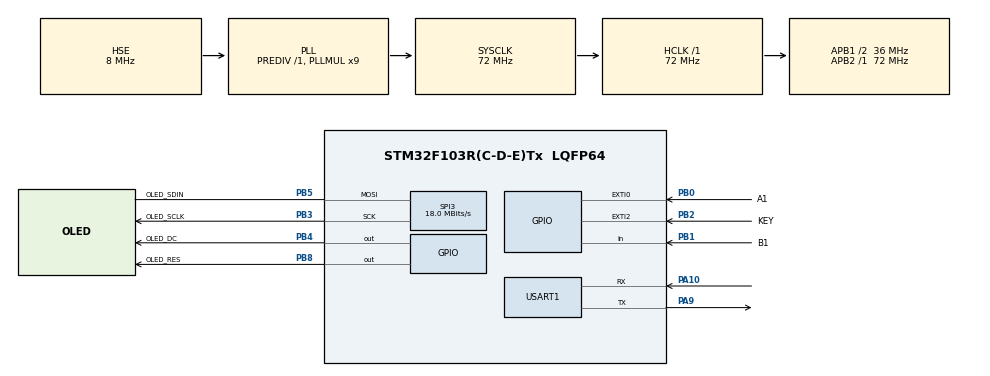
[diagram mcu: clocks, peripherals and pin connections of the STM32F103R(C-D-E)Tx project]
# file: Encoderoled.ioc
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Mcu.Family=STM32F1
Mcu.Name=STM32F103R(C-D-E)Tx
Mcu.Package=LQFP64
NVIC.EXTI0_IRQn=true\:0\:0\:false\:false\:true\:true\:true\:true
NVIC.PriorityGroup=NVIC_PRIORITYGROUP_4
PA10.Mode=Asynchronous
PA10.Signal=USART1_RX
PA13.Mode=Serial_Wire
PA13.Signal=SYS_JTMS-SWDIO
PA14.Mode=Serial_Wire
PA14.Signal=SYS_JTCK-SWCLK
PA9.Mode=Asynchronous
PA9.Signal=USART1_TX
PB0.GPIO_Label=A1
PB0.GPIO_ModeDefaultEXTI=GPIO_MODE_IT_FALLING
PB0.Signal=GPXTI0
PB1.GPIO_Label=B1
PB1.Signal=GPIO_Input
PB2.GPIO_Label=KEY
PB2.GPIO_ModeDefaultEXTI=GPIO_MODE_IT_FALLING
PB2.Signal=GPXTI2
PB3.GPIO_Label=OLED_SCLK
PB3.Mode=Simplex_Bidirectional_Master
PB3.Signal=SPI3_SCK
PB4.GPIO_Label=OLED_DC
PB4.Signal=GPIO_Output
PB5.GPIO_Label=OLED_SDIN
PB5.Mode=Simplex_Bidirectional_Master
PB5.Signal=SPI3_MOSI
PB8.GPIO_Label=OLED_RES
PB8.Signal=GPIO_Output
PD0-OSC_IN.Mode=HSE-External-Oscillator
PD0-OSC_IN.Signal=RCC_OSC_IN
PD1-OSC_OUT.Mode=HSE-External-Oscillator
PD1-OSC_OUT.Signal=RCC_OSC_OUT
ProjectManager.HeapSize=0x200
ProjectManager.StackSize=0x400
ProjectManager.TargetToolchain=MDK-ARM V5.32
RCC.AHBFreq_Value=72000000
RCC.APB1CLKDivider=RCC_HCLK_DIV2
RCC.APB1Freq_Value=36000000
RCC.APB1TimFreq_Value=72000000
RCC.APB2Freq_Value=72000000
RCC.APB2TimFreq_Value=72000000
RCC.HCLKFreq_Value=72000000
RCC.PLLMUL=RCC_PLL_MUL9
RCC.PLLSourceVirtual=RCC_PLLSOURCE_HSE
RCC.SYSCLKFreq_VALUE=72000000
RCC.SYSCLKSource=RCC_SYSCLKSOURCE_PLLCLK
RCC.USBFreq_Value=72000000
SPI3.CalculateBaudRate=18.0 MBits/s
SPI3.Direction=SPI_DIRECTION_1LINE
SPI3.Mode=SPI_MODE_MASTER
SPI3.VirtualType=VM_MASTER
USART1.VirtualMode=VM_ASYNC
board=custom

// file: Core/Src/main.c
/* USER CODE BEGIN Header */
/**
  ******************************************************************************
  * @file           : main.c
  * @brief          : Main program body
  ******************************************************************************
  * @attention
  *
  * Copyright (c) 2026 STMicroelectronics.
  * All rights reserved.
  *
  * This software is licensed under terms that can be found in the LICENSE file
  * in the root directory of this software component.
  * If no LICENSE file comes with this software, it is provided AS-IS.
  *
  ******************************************************************************
  */
/* USER CODE END Header */
#include "main.h"
#include "spi.h"
#include "usart.h"
#include "gpio.h"

/* USER CODE BEGIN Includes */
# include <stdio.h>
#include <stdbool.h>
#include "sh1106oled.h"
#include "sh1106oledfont.h"
#include "Encoder.h"
/* USER CODE END Includes */

void SystemClock_Config(void);

int main(void)
{

  /* MCU Configuration--------------------------------------------------------*/

  /* Reset of all peripherals, Initializes the Flash interface and the Systick. */
  HAL_Init();

  /* Configure the system clock */
  SystemClock_Config();

  /* Initialize all configured peripherals */
  MX_GPIO_Init();
  MX_USART1_UART_Init();
  MX_SPI3_Init();
  /* USER CODE BEGIN 2 */
	sh1106_init();          // 初始化 OLED 硬件（GPIO、SPI 配置已在 MX 初始化）
  clr_oled_screen();      // 清空显示缓冲区
  Init();                 // 编码器状态初始化（count=0，显示第0号图标）
  /* USER CODE END 2 */

  /* Infinite loop */
  /* USER CODE BEGIN WHILE */
  while (1)
  {
		MENU_show();
    /* USER CODE END WHILE */

  }
}

void SystemClock_Config(void)
{
  RCC_OscInitTypeDef RCC_OscInitStruct = {0};
  RCC_ClkInitTypeDef RCC_ClkInitStruct = {0};

  /** Initializes the RCC Oscillators according to the specified parameters
  * in the RCC_OscInitTypeDef structure.
  */
  RCC_OscInitStruct.OscillatorType = RCC_OSCILLATORTYPE_HSE;
  RCC_OscInitStruct.HSEState = RCC_HSE_ON;
  RCC_OscInitStruct.HSEPredivValue = RCC_HSE_PREDIV_DIV1;
  RCC_OscInitStruct.HSIState = RCC_HSI_ON;
  RCC_OscInitStruct.PLL.PLLState = RCC_PLL_ON;
  RCC_OscInitStruct.PLL.PLLSource = RCC_PLLSOURCE_HSE;
  RCC_OscInitStruct.PLL.PLLMUL = RCC_PLL_MUL9;
  if (HAL_RCC_OscConfig(&RCC_OscInitStruct) != HAL_OK)
  {
    Error_Handler();
  }

  /** Initializes the CPU, AHB and APB buses clocks
  */
  RCC_ClkInitStruct.ClockType = RCC_CLOCKTYPE_HCLK|RCC_CLOCKTYPE_SYSCLK
                              |RCC_CLOCKTYPE_PCLK1|RCC_CLOCKTYPE_PCLK2;
  RCC_ClkInitStruct.SYSCLKSource = RCC_SYSCLKSOURCE_PLLCLK;
  RCC_ClkInitStruct.AHBCLKDivider = RCC_SYSCLK_DIV1;
  RCC_ClkInitStruct.APB1CLKDivider = RCC_HCLK_DIV2;
  RCC_ClkInitStruct.APB2CLKDivider = RCC_HCLK_DIV1;

  if (HAL_RCC_ClockConfig(&RCC_ClkInitStruct, FLASH_LATENCY_2) != HAL_OK)
  {
    Error_Handler();
  }
}

/* USER CODE BEGIN 4 */
int fputc(int ch,FILE *f){
	HAL_UART_Transmit(&huart1,(uint8_t *)&ch,1,0xff);
	return ch;
}
//中断产生后给布尔变量设置状态
void HAL_GPIO_EXTI_Callback(uint16_t GPIO_Pin)
{
	GPIO_EXTI(GPIO_Pin);
}
/* USER CODE END 4 */

void Error_Handler(void)
{
  __disable_irq();
  while (1)
  {
  }
}
